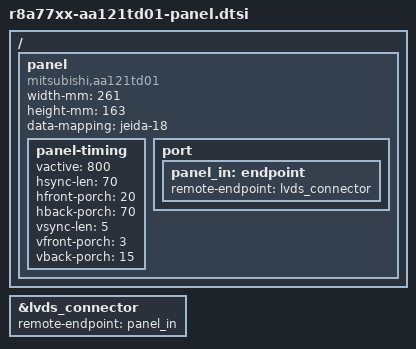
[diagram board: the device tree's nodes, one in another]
/* bench 25403.1.0 9814336c1193 */
/* bench 25403.1.1 70bdc17b10ed */
/* bench 25403.1.2 6c2a5c078adc */
/* bench 25403.1.3 aab73b01704f */
/*
 * Common file for the AA121TD01 panel connected to Renesas R-Car boards
 *
 * Copyright (C) 2015 Renesas Electronics Corp.
 */

/ {
	panel {
		compatible = "mitsubishi,aa121td01", "panel-lvds";

		width-mm = <261>;
		height-mm = <163>;
		data-mapping = "jeida-18";

		panel-timing {
			/* 1280x800 @60Hz */
/* bench 323.0.0 c4b8313dd0e2 */
/* bench 323.0.1 693449bd8989 */
/* bench 323.0.2 9084a30201ea */
/* bench 323.0.3 d5067de21578 */
/* bench 323.0.4 7a9d6a3f2a08 */
/* bench 323.0.5 b0ade657ecfd */
			vactive = <800>;
			hsync-len = <70>;
			hfront-porch = <20>;
			hback-porch = <70>;
			vsync-len = <5>;
			vfront-porch = <3>;
			vback-porch = <15>;
		};

		port {
			panel_in: endpoint {
				remote-endpoint = <&lvds_connector>;
			};
		};
	};
};

&lvds_connector {
	remote-endpoint = <&panel_in>;
};
